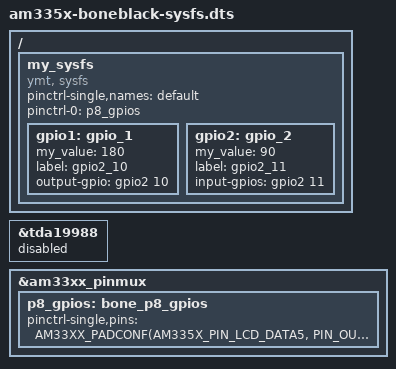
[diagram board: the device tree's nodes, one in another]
/dts-v1/;
/plugin/;

#include <dt-bindings/pinctrl/am33xx.h>
#include <dt-bindings/gpio/gpio.h>

/* Aşağıdaki, hazır kullanılan bazı pinlerin kullanılmasını iptal etmek için onu kullanan modülün durumunu disabled yapıyor. */
&tda19988 {
	status = "disabled";
};

&am33xx_pinmux {
	p8_gpios: bone_p8_gpios {
		pinctrl-single,pins = < 
					AM33XX_PADCONF(AM335X_PIN_LCD_DATA5, PIN_OUTPUT, MUX_MODE7) 
					AM33XX_PADCONF(AM335X_PIN_LCD_DATA6, PIN_INPUT, MUX_MODE7) 
		>;

	};

};

/ {
	my_sysfs: my_sysfs {
		compatible = "ymt, sysfs";
		pinctrl-single,names = "default";
		pinctrl-0 = <&p8_gpios>;
				
		gpio1: gpio_1{
			status = "okay";
			my_value = <180>;
			label = "gpio2_10";
			output-gpio = <&gpio2 10 GPIO_ACTIVE_HIGH>;
		};
			
		gpio2: gpio_2{
			status = "okay";
			my_value = <90>;
			label = "gpio2_11";
			input-gpios = <&gpio2 11 GPIO_ACTIVE_HIGH>;
		};
	};
};
